# apollo510 register map
Vendor: Ambiq Micro; Series: Apollo; File version: 1.0
CPU: CM55 r1p1, little endian, MPU, FPU, double-precision FPU, DSP, I-cache, D-cache, VTOR, ITCM, DTCM, 4 interrupt priority bits, 0 interrupts, 8 SAU regions
Registers are 32-bit, read-write, reset 0x0 unless marked. A register's access mark holds for its fields unless they carry their own. Offsets are from the block's base; [hi:lo] are bit positions; {n}, {i} and the like mark numbered series; 'fields as' and 'values as' point back to an identical list.

## CLKGEN — Clock Generator
Base 0x40004000
0x0C OCTRL — This register includes controls for autocalibration in addition to the RTC oscillator controls.
  [7] OSEL — Selects the RTC oscillator (1=LFRC, 0=XT)This selection bit and clocking the RTC with the external crystal (XT) are inoperable in silicon revisions A and B0.
    0=XT_512Hz (RTC uses the XT 512Hz); 1=LFRC_DIV2 (RTC uses the LFRC / 2)
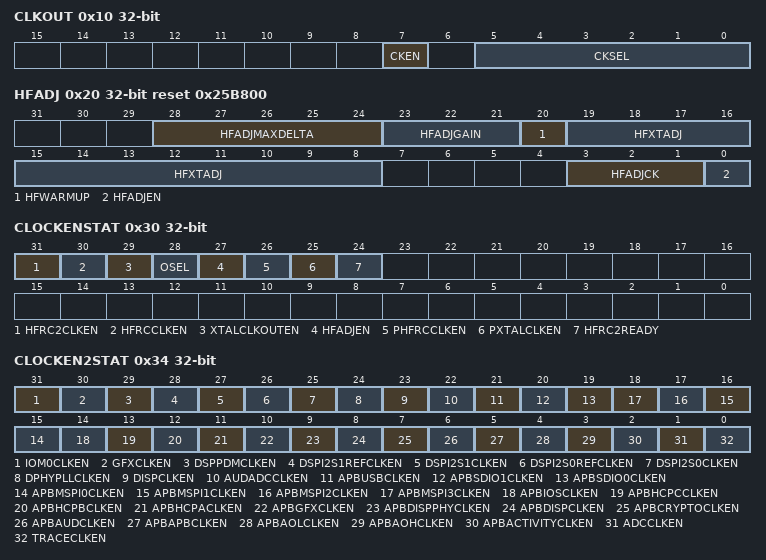
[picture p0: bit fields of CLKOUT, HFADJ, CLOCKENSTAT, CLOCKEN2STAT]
0x10 CLKOUT — This register enables the CLKOUT to the GPIOs, and selects the clock source to that.
  [7] CKEN — Enable the CLKOUT signal
    0=DIS (Disable CLKOUT); 1=EN (Enable CLKOUT)
  [5:0] CKSEL — Select the clock signal that will be observed on CLKOUT. For the Apollo510 family, the clock frequencies being observed are LFRC=900Hz, XT=32KHz, HFRC=48MHz, HFRC2=250MHz.
    0=LFRC_NOMINAL (LFRC clock source selection.); 1=XT_DIV2 (XT / 2 clock source selection); 2=XT_DIV4 (XT / 4 clock source selection); 3=XT_DIV8 (XT / 8 clock source selection); 4=XT_DIV16 (XT / 16 clock source selection); 5=XT_DIV32 (XT / 32 clock source selection); 16=RTC_1Hz (1 Hz as selected in RTC); 22=XT_DIV2M (XT / 2^21 clock source selection); 23=XT (XT clock source selection); 24=CG_100Hz (100 Hz as selected in CLKGEN); 35=LFRC_DIV2 (LFRC / 2 clock source selection); 36=LFRC_DIV32 (LFRC / 32 clock source selection); 37=LFRC_DIV512 (LFRC / 512 clock source selection); 38=LFRC_DIV32K (LFRC / 32768 clock source selection); 39=XT_DIV256 (XT / 256 clock source selection); 40=XT_DIV8K (XT / 8192 clock source selection); 41=XT_DIV64K (XT / 2^16 clock source selection); 42=ULFRC_DIV16 (Uncal LFRC / 16 clock source selection); 43=ULFRC_DIV128 (Uncal LFRC / 128 clock source selection); 44=ULFRC_DIV1K (Uncal LFRC / 1024 clock source selection); 45=ULFRC_DIV4K (Uncal LFRC / 4096 clock source selection); 46=ULFRC_DIV1M (Uncal LFRC / 2^20 clock source selection); 49=LFRC_DIV1M (LFRC / 2^20 clock source selection); 53=XTNE (XT (not autoenabled)); 54=XTNE_DIV16 (XT / 16 (not autoenabled)); 55=LFRCNE_DIV32 (LFRC / 32 (not autoenabled)); 57=LFRCNE (LFRC (not autoenabled) - Default for undefined values); 58=HFRC2_DIV64 (HFRC2 / 64 clock source selection); 59=HFRC2_DIV32 (HFRC2 / 32 clock source selection); 60=HFRC2_DIV16 (HFRC2 / 16 clock source selection); 61=HFRC2_DIV8 (HFRC2 / 8 clock source selection); 62=HFRC2_DIV2 (HFRC2 / 2 clock source selection); 63=HFRC2 (HFRC2 clock source selection)
0x20 HFADJ reset 0x25B800 — This register controls the HFRC adjustment. The HFRC clock can change with temperature and process corners, and this register controls the HFRC adjustment logic which reduces the fluctuations to the clock.
  [28:24] HFADJMAXDELTA — Maximum delta for HF Adjustments. 0=Disabled, 1-31=maximum delta step
    0=DISABLED (Maximum Delta function is disabled); 1=ENABLED (Maximum Delta function is enabled)
  [23:21] HFADJGAIN — Gain control for HFRC adjustment
    0=Gain_of_1 (HF Adjust with Gain of 1); 1=Gain_of_1_in_2 (HF Adjust with Gain of 0.5); 2=Gain_of_1_in_4 (HF Adjust with Gain of 0.25); 3=Gain_of_1_in_8 (HF Adjust with Gain of 0.125); 4=Gain_of_1_in_16 (HF Adjust with Gain of 0.0625); 5=Gain_of_1_in_32 (HF Adjust with Gain of 0.03125)
  [20] HFWARMUP — XT warmup period for HFRC adjustment
    0=1SEC (Autoadjust XT warmup period = 1-2 seconds); 1=2SEC (Autoadjust XT warmup period = 2-4 seconds)
  [19:8] HFXTADJ — Target HFRC adjustment value.
  [3:1] HFADJCK — Repeat period for HFRC adjustment
    0=4SEC (Autoadjust repeat period = 4 seconds); 1=16SEC (Autoadjust repeat period = 16 seconds); 2=32SEC (Autoadjust repeat period = 32 seconds); 3=64SEC (Autoadjust repeat period = 64 seconds); 4=128SEC (Autoadjust repeat period = 128 seconds); 5=256SEC (Autoadjust repeat period = 256 seconds); 6=512SEC (Autoadjust repeat period = 512 seconds); 7=1024SEC (Autoadjust repeat period = 1024 seconds)
  [0] HFADJEN — HFRC adjustment control
    0=DIS (Disable the HFRC adjustment); 1=EN (Enable the HFRC adjustment)
0x30 CLOCKENSTAT — This register provides the enable status to all the peripheral clocks.
  [31] HFRC2CLKEN — HFRC2 oscillator clock is on
  [30] HFRCCLKEN — HFRC oscillator clock is on
  [29] XTALCLKOUTEN — XTAL output clock is on
  [28] OSEL — RTC uses XT or LFRC
  [27] HFADJEN — HFADJ circuit is enabled
  [26] PHFRCCLKEN — At least one peripheral clock relying on HFRC is on
  [25] PXTALCLKEN — At least one peripheral clock relying on XTAL is on
  [24] HFRC2READY — HFRC2 clock is ready (goes high approx 5us after HFRC2 is powered up)
0x34 CLOCKEN2STAT — This is a continuation of the clock enable status.
  [31] IOM0CLKEN — IOM 0 clock is on
  [30] GFXCLKEN — GFX core clock is on
  [29] DSPPDMCLKEN — DSP PDM clock is on
  [28] DSPI2S1REFCLKEN — DSP I2S1 reference clock is on
  [27] DSPI2S1CLKEN — DSP I2S1 clock is on
  [26] DSPI2S0REFCLKEN — DISP I2S0 reference clock is on
  [25] DSPI2S0CLKEN — DISP I2S0 clock is on
  [24] DPHYPLLCLKEN — DPHY PLL clock is on
  [23] DISPCLKEN — DISP clock is on
  [22] AUDADCCLKEN — AUD ADC clock is on
  [21] APBUSBCLKEN — APB clock is on in the USB power domain
  [20] APBSDIO1CLKEN — APB clock is on in the SDIO1 power domain
  [19] APBSDIO0CLKEN — APB clock is on in the SDOI0 power domain
  [n+15] APBMSPI{n}CLKEN (n=0..3) — APB clock is on in the MSPI{n} power domain
  [14] APBIOSCLKEN — APB clock is on in the IOS power domain
  [13] APBHCPCCLKEN — APB clock is on in the HCP C power domain
  [12] APBHCPBCLKEN — APB clock is on in the HCP B power domain
  [11] APBHCPACLKEN — APB clock is on in the HCP A power domain
  [10] APBGFXCLKEN — APB clock is on in the GFX power domain
  [9] APBDISPPHYCLKEN — APB clock is on in the DISP PHY power domain
  [8] APBDISPCLKEN — APB clock is on in the DISP power domain
  [7] APBCRYPTOCLKEN — APB clock is on in the Crypto power domain
  [6] APBAUDCLKEN — APB clock is on in the AUD power domain
  [5] APBAPBCLKEN — APB clock is on in the APB power domain
  [4] APBAOLCLKEN — APB clock is on in the AOL power domain
  [3] APBAOHCLKEN — APB clock is on in the AOH power domain
  [2] APBACTIVITYCLKEN — APB clock is on in the Activity power domain
  [1] ADCCLKEN — ADC clock is on
  [0] TRACECLKEN — Trace clock is on
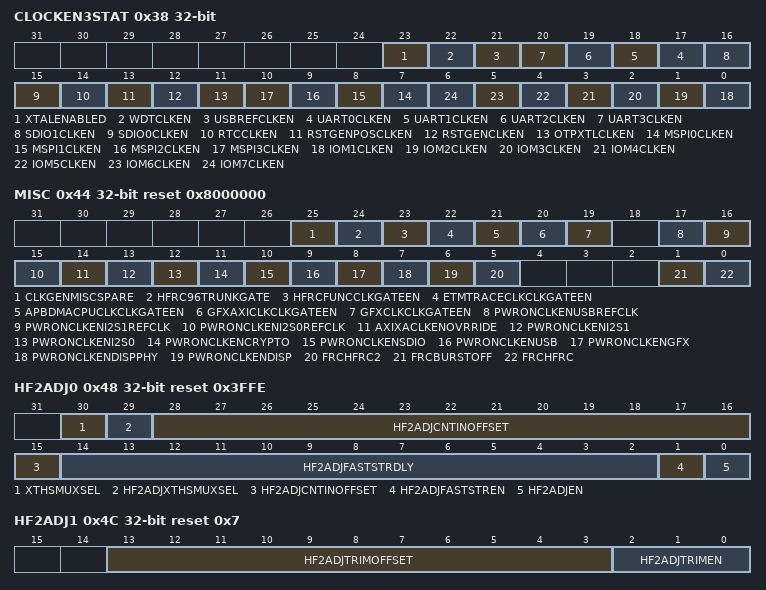
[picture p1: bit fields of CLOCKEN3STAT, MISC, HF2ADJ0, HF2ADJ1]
0x38 CLOCKEN3STAT — This is a continuation of the clock enable status.
  [23] XTALENABLED — XTAL oscillator enable
    0=XTAL_disabled (XTAL is disabled); 1=XTAL_enabled (XTAL is enabled)
  [22] WDTCLKEN — WDT clock is on
  [21] USBREFCLKEN — USB reference clock is on
  [n+17] UART{n}CLKEN (n=0..3) — UART {n} clock is on
  [16] SDIO1CLKEN — SDIO 1 clock is on
  [15] SDIO0CLKEN — SDIO 0 clock is on
  [14] RTCCLKEN — Real Time Clock clock is on
  [13] RSTGENPOSCLKEN — Reset generator POR clock is on
  [12] RSTGENCLKEN — Reset generator POR clock is on
  [11] OTPXTLCLKEN — OTP XTL clock is on
  [n+7] MSPI{n}CLKEN (n=0..3) — MSPI {n} clock is on
  [n-1] IOM{n}CLKEN (n=1..7) — IOM {n} clock is on
0x44 MISC reset 0x8000000 — This register controls a 'safe' mode for burst, which disables the clock when burst transition is happening. It also includes a register to force the HFRC during deep sleep. It is mainly used for debug and testing.
  [25] CLKGENMISCSPARE — Spare/Unused Chicken Bit
  [24] HFRC96TRUNKGATE — DO NOT USE. HFRC96_TRUNK_GATE. Setting this bit when BIT23=0, will kill HFRC root clock.
    0=DIS (Disable HFRC96_TRUNK_GATE); 1=EN (DO NOT USE. HFRC96_TRUNK_GATE. Setting this bit when BIT23=0, will kill HFRC root clock.)
  [23] HFRCFUNCCLKGATEEN — Chicken bit to enable clock gating on HFRC_FUNC_CLK
    0=DIS (Disable clock gate); 1=EN (Enable clock gate)
  [22] ETMTRACECLKCLKGATEEN — Chicken bit to enable clock gating on ETM TRACE CLK
    0=DIS (Disable clock gate); 1=EN (Enable clock gate)
  [21] APBDMACPUCLKCLKGATEEN — Clock gate enable for APB DMA clock
    0=FORCEON (APB DMA clock is forced ON); 1=NOFORCE (APB DMA clock is controlled by APB DMA CPU logic)
  [20] GFXAXICLKCLKGATEEN — Clock gate enable for GFX AXI clock
    0=FORCEON (GFX AXI clock is forced ON); 1=NOFORCE (GFX AXI clock is controlled by GFX logic)
  [19] GFXCLKCLKGATEEN — Clock gate enable for GFX clock
    0=FORCEON (GFX clock is forced ON); 1=NOFORCE (GFX clock is controlled by GFX logic)
  [17] PWRONCLKENUSBREFCLK — Chicken bit to disable Rev B clock enable during reset
    0=USBREFCLKENRST (Enable USB REF Clock to run during reset); 1=DEFEATURE (Chicken bit to revert to rev A)
  [16] PWRONCLKENI2S1REFCLK — Chicken bit to disable Rev B clock enable during reset
    0=I2S1REFCLKENRST (Enable I2S instance 1 Clock to run during reset); 1=DEFEATURE (Chicken bit to revert to rev A)
  [15] PWRONCLKENI2S0REFCLK — Chicken bit to disable Rev B clock enable during reset
    0=I2S0REFCLKENRST (Enable I2S instance 0 Clock to run during reset); 1=DEFEATURE (Chicken bit to revert to rev A)
  [14] AXIXACLKENOVRRIDE — Chicken bit to disable Rev B added clock gating
    0=DEFEATURE_DISABLED (Fine grain clock gating enabled); 1=DEFEATURE (AXI Clock enabled when core is not in Sleep mode)
  [13] PWRONCLKENI2S1 — Chicken bit to disable Rev B clock enable during reset
    0=I2S1CLKENRST (Enable I2S instance 1 engine Clock to run during reset); 1=DEFEATURE (Chicken bit to revert to rev A)
  [12] PWRONCLKENI2S0 — Chicken bit to disable Rev B clock enable during reset
    0=I2S0CLKENRST (Enable I2S instance 0 engine Clock to run during reset); 1=DEFEATURE (Chicken bit to revert to rev A)
  [11] PWRONCLKENCRYPTO — Chicken bit to disable Rev B clock enable during reset
    0=CRYPTOCLKENRST (Enable Cryto engine Clock to run during reset); 1=DEFEATURE (Chicken bit to revert to rev A)
  [10] PWRONCLKENSDIO — Chicken bit to disable Rev B clock enable during reset
    0=SDIOCLKENRST (Enable SDIO Clock to run during reset); 1=DEFEATURE (Chicken bit to revert to rev A)
  [9] PWRONCLKENUSB — Chicken bit to disable Rev B clock enable during reset
    0=USBCLKENRST (Enable USB Clock to run during reset); 1=DEFEATURE (Chicken bit to revert to rev A)
  [8] PWRONCLKENGFX — Chicken bit to disable Rev B clock enable during reset
    0=GFXCLKENRST (Enable GFX Clock to run during reset); 1=DEFEATURE (Chicken bit to revert to rev A)
  [7] PWRONCLKENDISPPHY — Chicken bit to disable Rev B clock enable during reset
    0=DISPPHYCLKENRST (Enable Display Phy Clock to run during reset); 1=DEFEATURE (Chicken bit to revert to rev A)
  [6] PWRONCLKENDISP — Chicken bit to disable Rev B clock enable during reset
    0=DISPCLKENRST (Enable Display Clock to run during reset); 1=DEFEATURE (Chicken bit to revert to rev A)
  [5] FRCHFRC2 — Force HFRC2 On.When changing a module's clock source to HFRC2, this bit must be set before changing the MUX select to HFRC2 and then cleared after setting the MUX select to HFRC2.
    0=NOFRC (Do not force HFRC2 on; stops in deep sleep mode.); 1=FRC (Force HFRC2 on; runs in deep sleep mode.)
  [1] FRCBURSTOFF — Force fclk, hclk, fclk_wic and fclk_pmu to be turned off during burst transition.
    0=BURSTCLKON (fclk, hclk and fclk_wic are turned on during the burst transition); 1=BURSTCLKOFF (fclk, hclk and fclk are turned off during burst transition)
  [0] FRCHFRC — Force HFRC On .
    0=NOFRC (HFRC stops in deep sleep mode); 1=FRC (HFRC runs in deep sleep mode)
0x48 HF2ADJ0 reset 0x3FFE — This register controls hf2adj enable, fast_start enable, fast_start_delay setting and counter input offset.
  [30] XTHSMUXSEL — Clock select for the high speed XTAL/EXTREF mux
    0=XTHS (Select the high speed XTAL); 1=EXTREF (Select external reference.)
  [29] HF2ADJXTHSMUXSEL — Clock select for HF2ADJ: 0=XTHS 1=EXTREF
  [28:15] HF2ADJCNTINOFFSET — Counter input offset
  [14:2] HF2ADJFASTSTRDLY — Fast_start_delay value setting
  [1] HF2ADJFASTSTREN — Fast_start_delay control
    0=DIS (Fast_start_delay disable); 1=EN (Fast_start_delay enable)
  [0] HF2ADJEN — HF2ADJ control
    0=DIS (HF2ADJ disable); 1=EN (HF2ADJ enable)
0x4C HF2ADJ1 reset 0x7 — This register controls hf2adj trimming enable and trimming offset.
  [13:3] HF2ADJTRIMOFFSET — HF2ADJ trimming offset. (signed number)
  [2:0] HF2ADJTRIMEN — HF2ADJ output selection
    0=TRIM_EN0 (0); 1=TRIM_EN1 (HF2ADJTRIMOUT); 2=TRIM_EN2 (HF2ADJTRIMOFFSET); 3=TRIM_EN3 (HF2ADJTRIMOUT + HF2ADJTRIMOFFSET); 4=TRIM_EN4 (HF2TUNE); 5=TRIM_EN5 (HF2ADJTRIMOUT + HF2TUNE); 6=TRIM_EN6 (HF2ADJTRIMOFFSET + HF2TUNE); 7=TRIM_EN7 (HF2ADJTRIMOUT + HF2ADJTRIMOFFSET + HF2TUNE)
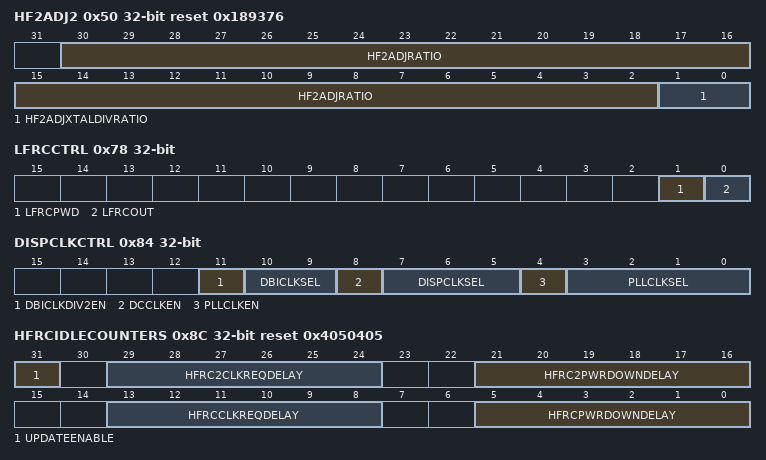
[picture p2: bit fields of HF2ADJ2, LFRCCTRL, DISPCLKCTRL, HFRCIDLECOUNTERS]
0x50 HF2ADJ2 reset 0x189376 — This register controls xtal32m divider ratio and HF2ADJ ration setting.
  [30:2] HF2ADJRATIO — HF2ADJ ratio setting.
  [1:0] HF2ADJXTALDIVRATIO — XTAL32MHz divider ratio for HF2ADJ.
    0=XTAL32M (XTAL32MHz); 1=XTAL32M_DIV2 (XTAL32MHz / 2); 2=XTAL32M_DIV4 (XTAL32MHz / 4); 3=XTAL32M_DIV8 (XTAL32MHz / 8)
0x54 HF2VAL — This register provides the read back of the HF2TUNE
  [10:0] HF2ADJTRIMOUT — HF2ADJ trimming output
0x78 LFRCCTRL — LFRC control
  [1] LFRCPWD — Power down LFRC
  [0] LFRCOUT — Disable LFRC output
0x84 DISPCLKCTRL — Provides ability to select the PLL reference clock, and derivative of the display clock
  [11] DBICLKDIV2EN — Enable for DBI CLK divider, 0x1: DBICLK/2, 0x0: bypass
  [10:9] DBICLKSEL — selection for DBI_CLK
    0=DBIB_CLK (DBIB_CLK from Display Controller); 1=FORMAT_CLK (format_clk from Display Controller); 2=PLL_CLK (pll_clk from DPHY)
  [8] DCCLKEN — Enable for the PLL clock through clkgen
  [7:5] DISPCLKSEL — Selection for PLL reference clock.
    0=OFF (Static value of 0 selected for DPHY clock input); 1=HFRC12 (12MHz sourced from the HFRC); 2=HFRC24 (24MHz sourced from the HFRC); 3=HFRC48 (48MHz sourced from the HFRC); 4=HFRC96 (96MHz sourced from the HFRC); 5=HFRC192 (192MHz sourced from the HFRC); 6=DPHYPLL
  [4] PLLCLKEN — Enable for the PLL clock through clkgen
  [3:0] PLLCLKSEL — Selection for PLL reference clock.
    0=OFF (Static value of 0 selected for DPHY clock input); 1=HFRC_24MHz (24MHz sourced from the HFRC); 2=HFRC_12MHz (12MHz sourced from the HFRC); 3=XTAL_HS (High Frequency XTAL input); 4=XTAL_HS_div2 (High Frequency XTAL input divide by 2); 5=EXTREFCLK (External reference clock input); 6=EXTREFCLK_div2 (External reference clock input divide by 2); 7=HFRC_48MHz (48MHz sourced from the HFRC); 8=HFRC_96MHz (96MHz sourced from the HFRC); 9=HFRC_192MHz (192MHz sourced from the HFRC)
0x88 CLKGENSPARES — CLKGEN Spare Regs
  [31:0] CLKGENSPARES — Placeholer spare registes that can be used as needed for future use
0x8C HFRCIDLECOUNTERS reset 0x4050405 — Provides SW controlled # idle cycles before powering down HFRC, HFRC2., core clock enable(s)
  [31] UPDATEENABLE — usage : Clear UPDATEENABLE or 1'b0; Update other bits fields of this register. Set this register to 1'b1 for HW to update.
  [29:24] HFRC2CLKREQDELAY — Enable for the PLL clock through clkgen
  [21:16] HFRC2PWRDOWNDELAY — Idle counter for HFRC2 POWER DOWN DELAY
  [13:8] HFRCCLKREQDELAY — Idle counter for HFRC CLK REQ DELAY
  [5:0] HFRCPWRDOWNDELAY — Idle counter for HFRC POWER DOWN DELAY
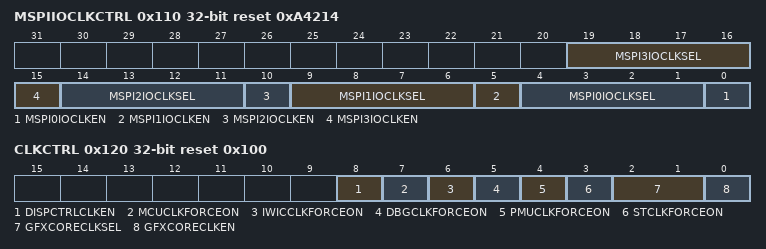
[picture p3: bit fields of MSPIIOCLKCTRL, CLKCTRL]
0x110 MSPIIOCLKCTRL reset 0xA4214 — Provides ability to select the MSPI clock, and derivative of the MSPI clock
  [19:16] MSPI3IOCLKSEL — selection for MSPI3 io clock
    7=HFRC_96MHz (96MHz sourced from the HFRC); 8=HFRC_192MHz (192MHz sourced from the HFRC); 9=HFRC2_125MHz (125MHz sourced from the HFRC2); 10=HFRC2_250MHz (250MHz sourced from the HFRC2)
  [5n] MSPI{n}IOCLKEN (n=0..3) — Enable for the MSPI{n} io clock through clkgen
    0=DIS (Disable io clock); 1=EN (Enable io clock)
  [14:11] MSPI2IOCLKSEL — selection for MSPI2 io clock
    7=HFRC_96MHz (96MHz sourced from the HFRC); 8=HFRC_192MHz (192MHz sourced from the HFRC)
  [9:6] MSPI1IOCLKSEL — selection for MSPI1 io clock
    values as MSPI2IOCLKSEL
  [4:1] MSPI0IOCLKSEL — selection for MSPI0 io clock
    values as MSPI3IOCLKSEL
0x120 CLKCTRL reset 0x100 — Provides ability to select and enable/force the GFX and MCU clocks
  [8] DISPCTRLCLKEN — Enable the 96MHz display controller clock
    0=DISABLE (Display controller clock disabled); 1=ENABLE (Display controller clock enabled)
  [7] MCUCLKFORCEON — Force the MCU clock to be always on (unused)
    0=OFF (Normal operation); 1=ON (Force MCU clock on)
  [6] IWICCLKFORCEON — Force the IWIC clock to be always on (unused)
    0=OFF (Normal operaration); 1=ON (Force IWIC clock on)
  [5] DBGCLKFORCEON — Force the DBG clock to be always on (unused)
    0=OFF (Normal operaration); 1=ON (Force DBG clock on)
  [4] PMUCLKFORCEON — Force the PMU clock to be always on (unused)
    0=OFF (Normal operaration); 1=ON (Force PMU clock on)
  [3] STCLKFORCEON — Force the ST clock to be always on
    0=OFF (Normal operaration); 1=ON (Force ST clock on)
  [2:1] GFXCORECLKSEL — selection for GFX CORE clock
    0=HFRC_96MHz (96MHz sourced from the HFRC); 1=HFRC_192MHz (192MHz sourced from the HFRC); 2=HFRC2_125MHz (125MHz sourced from the HFRC2); 3=HFRC2_250MHz (250MHz sourced from the HFRC2)
  [0] GFXCORECLKEN — Enable for the GFX CORE clock through clkgen
    0=DIS (Disable GFX clock); 1=EN (Enable GFX clock)
